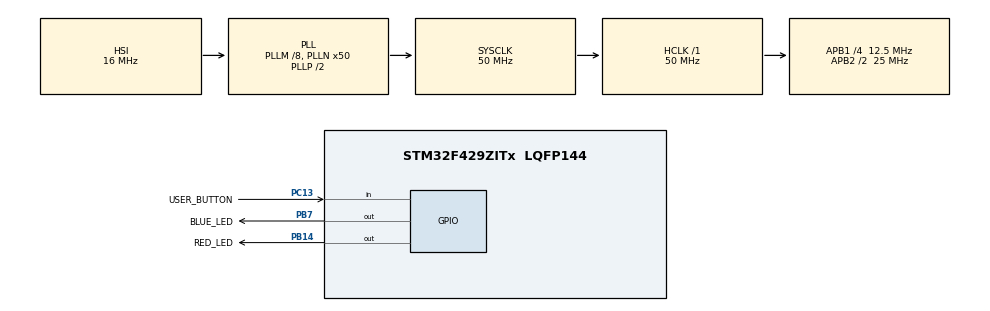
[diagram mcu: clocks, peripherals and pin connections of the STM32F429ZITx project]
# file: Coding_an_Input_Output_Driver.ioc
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Mcu.Family=STM32F4
Mcu.Name=STM32F429ZITx
Mcu.Package=LQFP144
NVIC.PriorityGroup=NVIC_PRIORITYGROUP_4
PA13.Mode=Serial_Wire
PA13.Signal=SYS_JTMS-SWDIO
PA14.Mode=Serial_Wire
PA14.Signal=SYS_JTCK-SWCLK
PB14.GPIO_Label=RED_LED
PB14.Signal=GPIO_Output
PB7.GPIO_Label=BLUE_LED
PB7.Signal=GPIO_Output
PC13.GPIO_Label=USER_BUTTON
PC13.Signal=GPIO_Input
PC14/OSC32_IN.Mode=LSE-External-Oscillator
PC14/OSC32_IN.Signal=RCC_OSC32_IN
PC15/OSC32_OUT.Mode=LSE-External-Oscillator
PC15/OSC32_OUT.Signal=RCC_OSC32_OUT
ProjectManager.HeapSize=0x200
ProjectManager.StackSize=0x400
ProjectManager.TargetToolchain=STM32CubeIDE
RCC.48MHZClocksFreq_Value=14285714.285714285
RCC.AHBFreq_Value=50000000
RCC.APB1CLKDivider=RCC_HCLK_DIV4
RCC.APB1Freq_Value=12500000
RCC.APB1TimFreq_Value=25000000
RCC.APB2CLKDivider=RCC_HCLK_DIV2
RCC.APB2Freq_Value=25000000
RCC.APB2TimCLKDivider=2
RCC.APB2TimFreq_Value=50000000
RCC.CortexFreq_Value=50000000
RCC.HCLKFreq_Value=50000000
RCC.HSE_VALUE=8000000
RCC.HSI_VALUE=16000000
RCC.PLLM=8
RCC.PLLMUL=RCC_PLL_MUL9
RCC.PLLN=50
RCC.PLLQ=7
RCC.PRESCALERUSB=RCC_USBCLKSOURCE_PLL_DIV1_5
RCC.SYSCLKFreq_VALUE=50000000
RCC.SYSCLKSource=RCC_SYSCLKSOURCE_PLLCLK
RCC.SYSCLKSourceVirtual=RCC_SYSCLKSOURCE_PLLCLK
RCC.USBFreq_Value=48000000
RCC.VCOOutputFreq_Value=100000000
board=NUCLEO-F429ZI

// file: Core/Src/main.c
/* USER CODE BEGIN Header */
/**
  ******************************************************************************
  * @file           : main.c
  * @brief          : Main program body
  ******************************************************************************
  * @attention
  *
  * Copyright (c) 2023 STMicroelectronics.
  * All rights reserved.
  *
  * This software is licensed under terms that can be found in the LICENSE file
  * in the root directory of this software component.
  * If no LICENSE file comes with this software, it is provided AS-IS.
  *
  ******************************************************************************
  */
/* USER CODE END Header */
#include "main.h"
#include "gpio.h"

/* USER CODE BEGIN PV */
uint8_t input_status=0;
/* USER CODE END PV */

void SystemClock_Config(void);

int main(void)
{

  /* MCU Configuration--------------------------------------------------------*/

  /* Reset of all peripherals, Initializes the Flash interface and the Systick. */
  HAL_Init();

  /* Configure the system clock */
  SystemClock_Config();

  /* Initialize all configured peripherals */
  MX_GPIO_Init();

  /* Infinite loop */
  /* USER CODE BEGIN WHILE */
  while (1)
  {
	  input_status=HAL_GPIO_ReadPin(USER_BUTTON_GPIO_Port, USER_BUTTON_Pin);

	  HAL_GPIO_WritePin(RED_LED_GPIO_Port, RED_LED_Pin, input_status);
	  HAL_GPIO_WritePin(BLUE_LED_GPIO_Port, BLUE_LED_Pin, !input_status);
  }
  /* USER CODE END 3 */
}

void SystemClock_Config(void)
{
  RCC_OscInitTypeDef RCC_OscInitStruct = {0};
  RCC_ClkInitTypeDef RCC_ClkInitStruct = {0};

  /** Configure the main internal regulator output voltage
  */
  __HAL_RCC_PWR_CLK_ENABLE();
  __HAL_PWR_VOLTAGESCALING_CONFIG(PWR_REGULATOR_VOLTAGE_SCALE3);

  /** Initializes the RCC Oscillators according to the specified parameters
  * in the RCC_OscInitTypeDef structure.
  */
  RCC_OscInitStruct.OscillatorType = RCC_OSCILLATORTYPE_HSI;
  RCC_OscInitStruct.HSIState = RCC_HSI_ON;
  RCC_OscInitStruct.HSICalibrationValue = RCC_HSICALIBRATION_DEFAULT;
  RCC_OscInitStruct.PLL.PLLState = RCC_PLL_ON;
  RCC_OscInitStruct.PLL.PLLSource = RCC_PLLSOURCE_HSI;
  RCC_OscInitStruct.PLL.PLLM = 8;
  RCC_OscInitStruct.PLL.PLLN = 50;
  RCC_OscInitStruct.PLL.PLLP = RCC_PLLP_DIV2;
  RCC_OscInitStruct.PLL.PLLQ = 7;
  if (HAL_RCC_OscConfig(&RCC_OscInitStruct) != HAL_OK)
  {
    Error_Handler();
  }

  /** Initializes the CPU, AHB and APB buses clocks
  */
  RCC_ClkInitStruct.ClockType = RCC_CLOCKTYPE_HCLK|RCC_CLOCKTYPE_SYSCLK
                              |RCC_CLOCKTYPE_PCLK1|RCC_CLOCKTYPE_PCLK2;
  RCC_ClkInitStruct.SYSCLKSource = RCC_SYSCLKSOURCE_PLLCLK;
  RCC_ClkInitStruct.AHBCLKDivider = RCC_SYSCLK_DIV1;
  RCC_ClkInitStruct.APB1CLKDivider = RCC_HCLK_DIV4;
  RCC_ClkInitStruct.APB2CLKDivider = RCC_HCLK_DIV2;

  if (HAL_RCC_ClockConfig(&RCC_ClkInitStruct, FLASH_LATENCY_1) != HAL_OK)
  {
    Error_Handler();
  }
}

void Error_Handler(void)
{
  __disable_irq();
  while (1)
  {
  }
}
